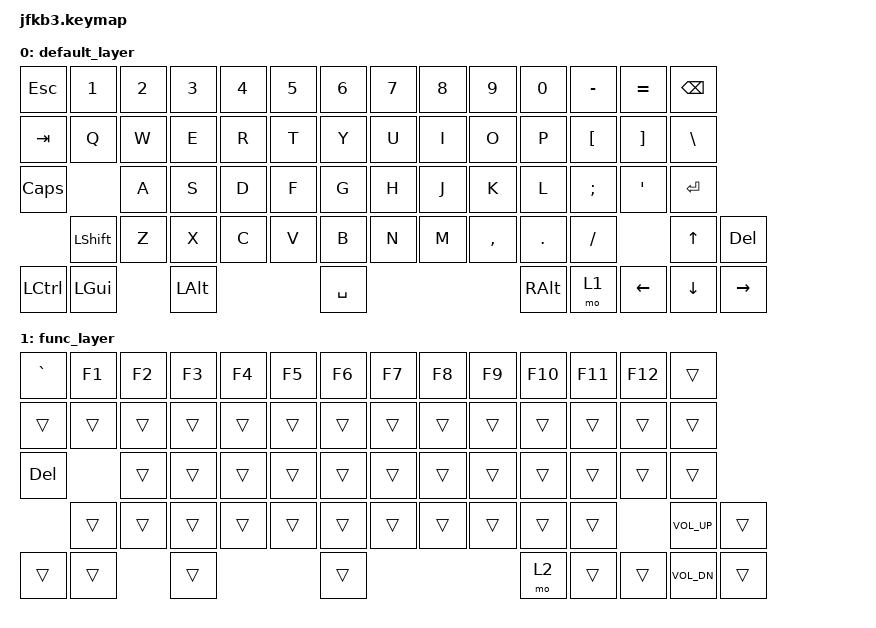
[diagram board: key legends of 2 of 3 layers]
#include <behaviors.dtsi>
#include <dt-bindings/zmk/keys.h>
#include <dt-bindings/zmk/bt.h>
#include <dt-bindings/zmk/outputs.h>

/ {
    keymap {
        compatible = "zmk,keymap";

        default_layer {
            bindings = <
                &kp ESC         &kp N1          &kp N2          &kp N3      &kp N4          &kp N5      &kp N6          &kp N7      &kp N8      &kp N9      &kp N0          &kp MINUS           &kp EQUAL                              &kp BACKSPACE
                &kp TAB                         &kp Q           &kp W       &kp E           &kp R       &kp T           &kp Y       &kp U       &kp I       &kp O           &kp P               &kp LEFT_BRACKET    &kp RIGHT_BRACKET   &kp BACKSLASH
                &kp CLCK                        &kp A           &kp S       &kp D           &kp F       &kp G           &kp H       &kp J       &kp K       &kp L           &kp SEMICOLON       &kp APOSTROPHE      &kp ENTER
                                &kp LEFT_SHIFT      &kp Z           &kp X       &kp C           &kp V       &kp B           &kp N       &kp M       &kp COMMA   &kp PERIOD      &kp SLASH                                &kp UP              &kp DELETE
                &kp LCTRL       &kp LGUI                        &kp LALT                                &kp SPACE                                           &kp RALT        &mo 1               &kp LEFT            &kp DOWN            &kp RIGHT
            >;
        };

        func_layer {
            bindings = <
                &kp GRAVE    &kp F1    &kp F2      &kp F3           &kp F4  &kp F5       &kp F6  &kp F7  &kp F8  &kp F9  &kp F10  &kp F11  &kp F12 &trans
                &trans    &trans    &trans      &trans           &trans  &trans       &trans  &trans  &trans  &trans  &trans  &trans  &trans &trans
                &kp DELETE          &trans          &trans  &trans           &trans  &trans       &trans  &trans  &trans  &trans  &trans  &trans  &trans
                &trans          &trans          &trans      &trans       &trans  &trans  &trans  &trans  &trans  &trans  &trans  &kp C_VOL_UP  &trans
                &trans          &trans          &trans      &trans           &mo 2  &trans       &trans  &kp C_VOL_DN  &trans
            >;
        };

        config_layer {
            bindings = <
                &bt BT_CLR_ALL      &bt BT_SEL 0      &bt BT_SEL 1      &bt BT_SEL 2      &bt BT_SEL 3      &trans      &trans      &trans      &trans      &trans      &trans      &trans      &trans
                &trans      &trans      &trans      &trans      &trans      &trans      &trans      &trans      &trans      &trans      &trans      &trans      &trans      &trans
                &trans      &trans      &trans      &trans      &trans      &trans      &trans      &trans      &trans      &trans      &trans      &trans      &trans
                &trans      &trans      &trans      &trans      &trans      &bootloader      &trans      &trans      &trans      &trans      &trans      &trans      &bt BT_CLR_ALL
                &trans      &trans      &trans      &trans      &trans      &trans      &trans      &trans      &trans
            >;
        };
    };
};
